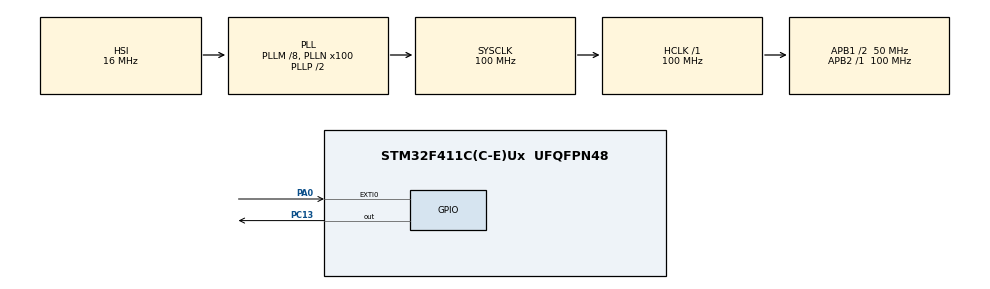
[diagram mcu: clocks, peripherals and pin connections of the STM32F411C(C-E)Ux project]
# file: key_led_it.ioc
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FREERTOS.Tasks01=key_task,24,128,key_task_func,Default,NULL,Dynamic,NULL,NULL;led_task,32,128,led_task_func,Default,NULL,Dynamic,NULL,NULL
Mcu.Family=STM32F4
Mcu.Name=STM32F411C(C-E)Ux
Mcu.Package=UFQFPN48
NVIC.EXTI0_IRQn=true\:5\:0\:false\:false\:true\:true\:true\:true\:true
NVIC.PriorityGroup=NVIC_PRIORITYGROUP_4
NVIC.TIM1_UP_TIM10_IRQn=true\:15\:0\:false\:false\:true\:false\:false\:true\:true
NVIC.TimeBase=TIM1_UP_TIM10_IRQn
NVIC.TimeBaseIP=TIM10
PA0-WKUP.GPIO_ModeDefaultEXTI=GPIO_MODE_IT_FALLING
PA0-WKUP.GPIO_PuPd=GPIO_PULLUP
PA0-WKUP.Signal=GPXTI0
PA13.Mode=Serial_Wire
PA13.Signal=SYS_JTMS-SWDIO
PA14.Mode=Serial_Wire
PA14.Signal=SYS_JTCK-SWCLK
PC13-ANTI_TAMP.PinState=GPIO_PIN_SET
PC13-ANTI_TAMP.Signal=GPIO_Output
ProjectManager.HeapSize=0x200
ProjectManager.StackSize=0x400
ProjectManager.TargetToolchain=MDK-ARM V5.32
RCC.48MHZClocksFreq_Value=50000000
RCC.AHBFreq_Value=100000000
RCC.APB1CLKDivider=RCC_HCLK_DIV2
RCC.APB1Freq_Value=50000000
RCC.APB1TimFreq_Value=100000000
RCC.APB2Freq_Value=100000000
RCC.APB2TimFreq_Value=100000000
RCC.CortexFreq_Value=100000000
RCC.HCLKFreq_Value=100000000
RCC.HSE_VALUE=25000000
RCC.HSI_VALUE=16000000
RCC.LSE_VALUE=32768
RCC.PLLM=8
RCC.PLLN=100
RCC.SYSCLKFreq_VALUE=100000000
RCC.SYSCLKSource=RCC_SYSCLKSOURCE_PLLCLK
RCC.VCOOutputFreq_Value=200000000
VP_FREERTOS_VS_CMSIS_V2.Mode=CMSIS_V2
VP_SYS_VS_tim10.Mode=TIM10
board=custom

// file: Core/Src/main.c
/* USER CODE BEGIN Header */
/**
  ******************************************************************************
  * @file           : main.c
  * @brief          : Main program body
  ******************************************************************************
  * @attention
  *
  * Copyright (c) 2026 STMicroelectronics.
  * All rights reserved.
  *
  * This software is licensed under terms that can be found in the LICENSE file
  * in the root directory of this software component.
  * If no LICENSE file comes with this software, it is provided AS-IS.
  *
  ******************************************************************************
  */
/* USER CODE END Header */
#include "main.h"
#include "cmsis_os.h"
#include "gpio.h"

void SystemClock_Config(void);
void MX_FREERTOS_Init(void);

int main(void)
{

  /* MCU Configuration--------------------------------------------------------*/

  /* Reset of all peripherals, Initializes the Flash interface and the Systick. */
  HAL_Init();

  /* Configure the system clock */
  SystemClock_Config();

  /* Initialize all configured peripherals */
  MX_GPIO_Init();

  /* Init scheduler */
  osKernelInitialize();  /* Call init function for freertos objects (in freertos.c) */
  MX_FREERTOS_Init();

  /* Start scheduler */
  osKernelStart();
  /* We should never get here as control is now taken by the scheduler */
  /* Infinite loop */
  while (1)
  {

  }
}

void SystemClock_Config(void)
{
  RCC_OscInitTypeDef RCC_OscInitStruct = {0};
  RCC_ClkInitTypeDef RCC_ClkInitStruct = {0};

  /** Configure the main internal regulator output voltage
  */
  __HAL_RCC_PWR_CLK_ENABLE();
  __HAL_PWR_VOLTAGESCALING_CONFIG(PWR_REGULATOR_VOLTAGE_SCALE1);

  /** Initializes the RCC Oscillators according to the specified parameters
  * in the RCC_OscInitTypeDef structure.
  */
  RCC_OscInitStruct.OscillatorType = RCC_OSCILLATORTYPE_HSI;
  RCC_OscInitStruct.HSIState = RCC_HSI_ON;
  RCC_OscInitStruct.HSICalibrationValue = RCC_HSICALIBRATION_DEFAULT;
  RCC_OscInitStruct.PLL.PLLState = RCC_PLL_ON;
  RCC_OscInitStruct.PLL.PLLSource = RCC_PLLSOURCE_HSI;
  RCC_OscInitStruct.PLL.PLLM = 8;
  RCC_OscInitStruct.PLL.PLLN = 100;
  RCC_OscInitStruct.PLL.PLLP = RCC_PLLP_DIV2;
  RCC_OscInitStruct.PLL.PLLQ = 4;
  if (HAL_RCC_OscConfig(&RCC_OscInitStruct) != HAL_OK)
  {
    Error_Handler();
  }

  /** Initializes the CPU, AHB and APB buses clocks
  */
  RCC_ClkInitStruct.ClockType = RCC_CLOCKTYPE_HCLK|RCC_CLOCKTYPE_SYSCLK
                              |RCC_CLOCKTYPE_PCLK1|RCC_CLOCKTYPE_PCLK2;
  RCC_ClkInitStruct.SYSCLKSource = RCC_SYSCLKSOURCE_PLLCLK;
  RCC_ClkInitStruct.AHBCLKDivider = RCC_SYSCLK_DIV1;
  RCC_ClkInitStruct.APB1CLKDivider = RCC_HCLK_DIV2;
  RCC_ClkInitStruct.APB2CLKDivider = RCC_HCLK_DIV1;

  if (HAL_RCC_ClockConfig(&RCC_ClkInitStruct, FLASH_LATENCY_3) != HAL_OK)
  {
    Error_Handler();
  }
}

void HAL_TIM_PeriodElapsedCallback(TIM_HandleTypeDef *htim)
{
  if (htim->Instance == TIM10) {
    HAL_IncTick();
  }
}

void Error_Handler(void)
{
  __disable_irq();
  while (1)
  {
  }
}

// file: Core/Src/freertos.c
/* USER CODE BEGIN Header */
/**
  ******************************************************************************
  * File Name          : freertos.c
  * Description        : Code for freertos applications
  ******************************************************************************
  * @attention
  *
  * Copyright (c) 2026 STMicroelectronics.
  * All rights reserved.
  *
  * This software is licensed under terms that can be found in the LICENSE file
  * in the root directory of this software component.
  * If no LICENSE file comes with this software, it is provided AS-IS.
  *
  ******************************************************************************
  */
/* USER CODE END Header */

#include "FreeRTOS.h"
#include "task.h"
#include "main.h"
#include "cmsis_os.h"

/* USER CODE BEGIN Includes */

#include "rtos.h"
#include "queue.h"
#include "gpio.h"

/* USER CODE END Includes */

/* USER CODE BEGIN Variables */

QueueHandle_t it_to_key, key_to_led;

/* USER CODE END Variables */
/* Definitions for key_task */
osThreadId_t key_taskHandle;
const osThreadAttr_t key_task_attributes = {
  .name = "key_task",
  .stack_size = 128 * 4,
  .priority = (osPriority_t) osPriorityNormal,
};
/* Definitions for led_task */
osThreadId_t led_taskHandle;
const osThreadAttr_t led_task_attributes = {
  .name = "led_task",
  .stack_size = 128 * 4,
  .priority = (osPriority_t) osPriorityAboveNormal,
};

void key_task_func(void *argument);
void led_task_func(void *argument);

void MX_FREERTOS_Init(void); /* (MISRA C 2004 rule 8.1) */

void MX_FREERTOS_Init(void) {

  /* USER CODE BEGIN RTOS_QUEUES */
  /* add queues, ... */

  it_to_key = xQueueCreate(16, sizeof(it_msg_t));
  key_to_led = xQueueCreate(16, sizeof(key_press_status_t));

  /* USER CODE END RTOS_QUEUES */

  /* Create the thread(s) */
  /* creation of key_task */
  key_taskHandle = osThreadNew(key_task_func, NULL, &key_task_attributes);

  /* creation of led_task */
  led_taskHandle = osThreadNew(led_task_func, NULL, &led_task_attributes);

}

void key_task_func(void *argument)
{
  /* USER CODE BEGIN key_task_func */

  it_msg_t msg = {
    .type = IT_FALLING,
    .tick = 0
  };
  uint32_t last_tick = 0;
  key_press_status_t status = KEY_NOT_PRESS;

  /* Infinite loop */
  for(;;)
  {
    xQueueReceive(it_to_key, &msg, portMAX_DELAY);
    if (msg.type == IT_FALLING) {
      last_tick = msg.tick;
    }
    else {
      if (msg.tick - last_tick > 500)
        status = KEY_LONG_PRESS;
      else if (msg.tick - last_tick > 20)
        status = KEY_PRESS;
      else
        continue;
      xQueueSendToBack(key_to_led, &status, portMAX_DELAY);
    }

    osDelay(1);
  }
  /* USER CODE END key_task_func */
}

void led_task_func(void *argument)
{
  /* USER CODE BEGIN led_task_func */

  key_press_status_t status = KEY_NOT_PRESS;

  /* Infinite loop */
  for(;;)
  {
    xQueueReceive(key_to_led, &status, portMAX_DELAY);
    if (status == KEY_PRESS)
      HAL_GPIO_WritePin(GPIOC, GPIO_PIN_13, GPIO_PIN_RESET);
    else if (status == KEY_LONG_PRESS)
      HAL_GPIO_WritePin(GPIOC, GPIO_PIN_13, GPIO_PIN_SET);

    osDelay(1);
  }
  /* USER CODE END led_task_func */
}
